# CSI_TX_IF0_TX_SHIM_VBUSP_MMR_CSI2TXIF register map
Vendor: Texas Instruments
Peripheral module from a debugger description file (folder J7ES).
Registers are 32-bit, read-write, reset values left out (the file's numbers can be read two ways) unless marked. A register's access mark holds for its fields unless they carry their own. Offsets are as the file gives them; lines under a group give offsets from that group; [hi:lo] are bit positions; {n}, {i} and the like mark numbered series; 'fields as' and 'values as' point back to an identical list; <NAME> marks a mode.

## CSI_TX_IF0_TX_SHIM_VBUSP_MMR_CSI2TXIF
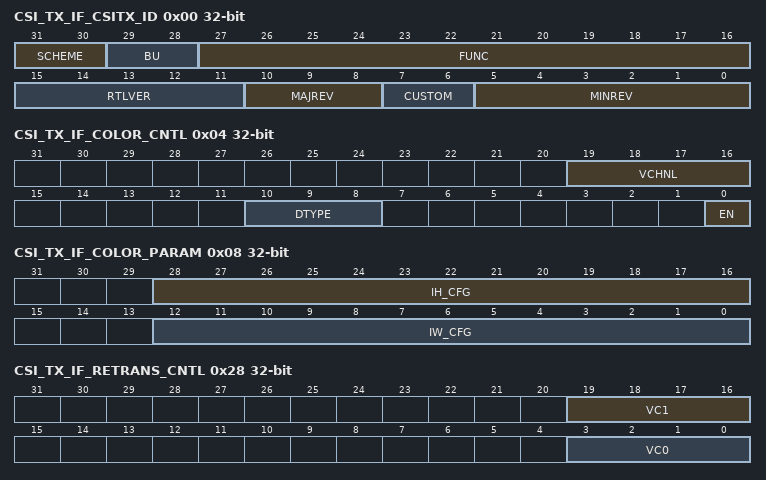
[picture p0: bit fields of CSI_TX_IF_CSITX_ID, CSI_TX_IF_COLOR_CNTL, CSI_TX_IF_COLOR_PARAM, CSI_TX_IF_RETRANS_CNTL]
0x00 CSI_TX_IF_CSITX_ID ro — PID
  [31:30] SCHEME
  [29:28] BU
  [27:16] FUNC — function
  [15:11] RTLVER — rtl version
  [10:8] MAJREV — major
  [7:6] CUSTOM
  [5:0] MINREV — min
0x04 CSI_TX_IF_COLOR_CNTL — color bar control register
  [19:16] VCHNL — color bar virtual channel
  [10:8] DTYPE — color bar data type, data sel
  [0] EN
0x08 CSI_TX_IF_COLOR_PARAM — color bar frame parameters
  [28:16] IH_CFG — input height in units of pixels minus 1.
  [12:0] IW_CFG — input width in units of pixels minus 1.
0x0C CSI_TX_IF_COLOR_START_DELAY — delay from starting first line after enabling
  [31:0] LINE_DELAY — delay in terms of main clock cycles before sending first line after enabling.
0x20 CSI_TX_IF_COLOR_LINE_DELAY — last line start to next line start delay
  [31:0] LINE_DELAY — delay in terms of main clock cycles from line start to next line start
0x24 CSI_TX_IF_COLOR_FRAME_DELAY — line start to next frame start delay
  [31:0] FRAME_DELAY — delay in terms of main clock cycles from last line start to start of next frame
0x28 CSI_TX_IF_RETRANS_CNTL — retransmit control register
  [19:16] VC1 — virtual channel of csi tx to send out stream4 interface
  [3:0] VC0 — virtual channel of csi tx to send out stream3 interface
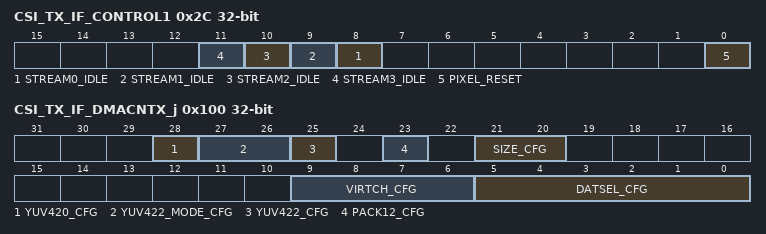
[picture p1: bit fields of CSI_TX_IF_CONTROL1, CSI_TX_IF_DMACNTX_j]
0x2C CSI_TX_IF_CONTROL1 access per field — control register for csi tx wrapper
  [n+8] STREAM{n}_IDLE ro (n=0..3) — indicates if stream interface is idle(1) or not(0)
  [0] PIXEL_RESET rw — reset for the pixeal interface.
0x40 CSI_TX_IF_F2F_DELAY_y — last line start to next frame start. Configuration for each of 16 virtual channels. Offset = 40h + (y * 4h); where y = 0h to Fh
  [31:0] DELAY — counter value delay of last line start of frame to first line of next frame
0x100 CSI_TX_IF_DMACNTX_j — DMA Channel Context. Configuration for each of 32 possible threads. Illegal to program 2 threads with same virtual channel and data type values Offset = 100h + (j * 20h); where j = 0h to 1Fh
  [28] YUV420_CFG — yuv422 format enable
  [27:26] YUV422_MODE_CFG — yuv422 mode
  [25] YUV422_CFG — yuv422 format enable
  [23] PACK12_CFG — pack12 format enable 0.
  [21:20] SIZE_CFG — data size shift when unpacking,
  [9:6] VIRTCH_CFG — CSI virtual channel index.
  [5:0] DATSEL_CFG — CSI data type index.
0x104 CSI_TX_IF_L2L_DELAY_j — line to line delay. Configuration for each of 32 possible channel contexts. Offset = 104h + (j * 20h); where j = 0h to 1Fh
  [31:0] DELAY — counter value delay line start to next line start within a frame
